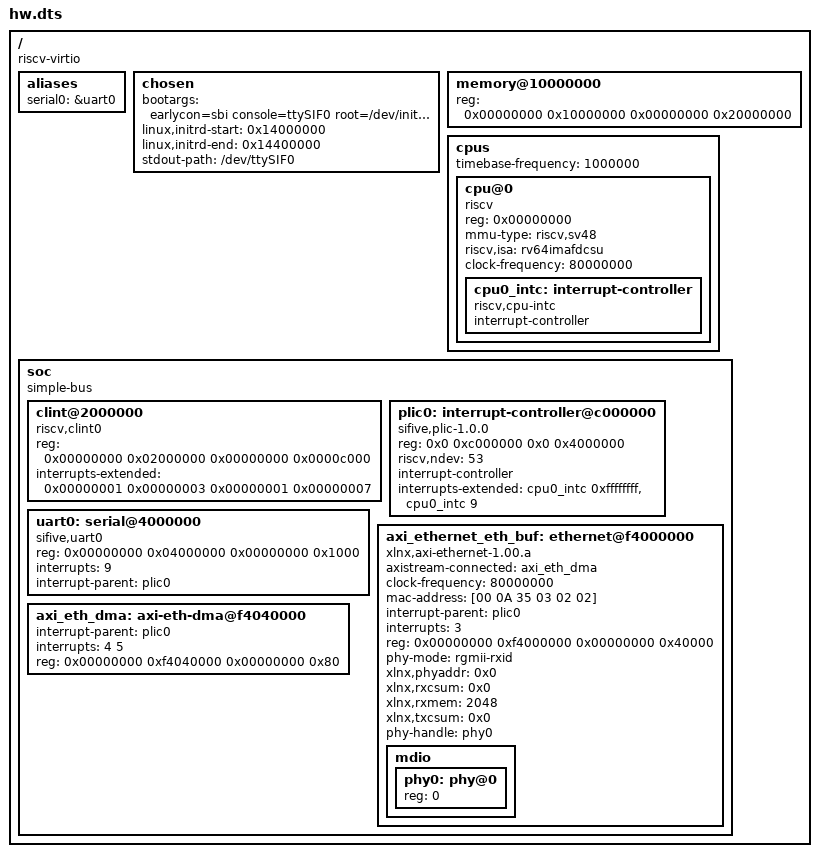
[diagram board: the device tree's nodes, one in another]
/dts-v1/;
// version:		17
// last_comp_version:	16
// boot_cpuid_phys:	0x0

/ {
    #address-cells = <0x00000002>;
    #size-cells = <0x00000002>;
    compatible = "riscv-virtio";

    aliases {
        serial0 = &uart0;
    };

    chosen {
        bootargs = "earlycon=sbi console=ttySIF0 root=/dev/initrd";
        linux,initrd-start = <0x14000000>;
        linux,initrd-end = <0x14400000>;
        stdout-path = "/dev/ttySIF0";
    };

    memory@10000000 {
        device_type = "memory";
        reg = <0x00000000 0x10000000 0x00000000 0x20000000>;
    };
    cpus {
        #address-cells = <0x00000001>;
        #size-cells = <0x00000000>;
        timebase-frequency = <1000000>;
        cpu@0 {
            device_type = "cpu";
            reg = <0x00000000>;
            mmu-type = "riscv,sv48";
            status = "okay";
            riscv,isa = "rv64imafdcsu";
            compatible = "riscv";
            clock-frequency = <80000000>;
            phandle = <0x00000002>;
            cpu0_intc: interrupt-controller {
                #interrupt-cells = <0x00000001>;
                interrupt-controller;
                compatible = "riscv,cpu-intc";
                phandle = <0x00000001>;
            };
        };
    };
    soc {
        #address-cells = <0x00000002>;
        #size-cells = <0x00000002>;
        ranges;
        compatible = "simple-bus";
        clint@2000000 {
            reg = <0x00000000 0x02000000 0x00000000 0x0000c000>;
            interrupts-extended = <0x00000001 0x00000003 0x00000001 0x00000007>;
            compatible = "riscv,clint0";
        };
        plic0: interrupt-controller@c000000 {
            #interrupt-cells = <1>;
            #address-cells = <1>;
            compatible = "sifive,plic-1.0.0";
            reg = <0x0 0xc000000 0x0 0x4000000>;
            riscv,ndev = <53>;
            interrupt-controller;
            interrupts-extended = <&cpu0_intc 0xffffffff &cpu0_intc 9>;
        };
        uart0: serial@4000000 {
            reg = <0x00000000 0x04000000 0x00000000 0x1000>;
            interrupts = <9>;
            interrupt-parent = <&plic0>;
            compatible = "sifive,uart0";
        };
        axi_ethernet_eth_buf: ethernet@f4000000 {
            axistream-connected = <&axi_eth_dma>;
            clock-frequency = <80000000>;
            compatible = "xlnx,axi-ethernet-1.00.a";
            device_type = "network";
            mac-address = [00 0A 35 03 02 02];
            interrupt-parent = <&plic0>;
            interrupts = <3>;
            reg = <0x00000000 0xf4000000 0x00000000 0x40000>;
            phy-mode = "rgmii-rxid";
            xlnx,phyaddr = <0x0>;
            xlnx,rxcsum = <0x0>;
            xlnx,rxmem = <2048>;
            xlnx,txcsum = <0x0>;
            phy-handle = <&phy0>;
            mdio {
                #address-cells = <1>;
                #size-cells = <0>;
                phy0: phy@0 {
                    device_type = "ethernet-phy";
                    reg = <0>;
                };
            };
        };
        axi_eth_dma: axi-eth-dma@f4040000 {
            interrupt-parent = <&plic0>;
            interrupts = <4 5>;
            reg = <0x00000000 0xf4040000 0x00000000 0x80>;
        };
    };
};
